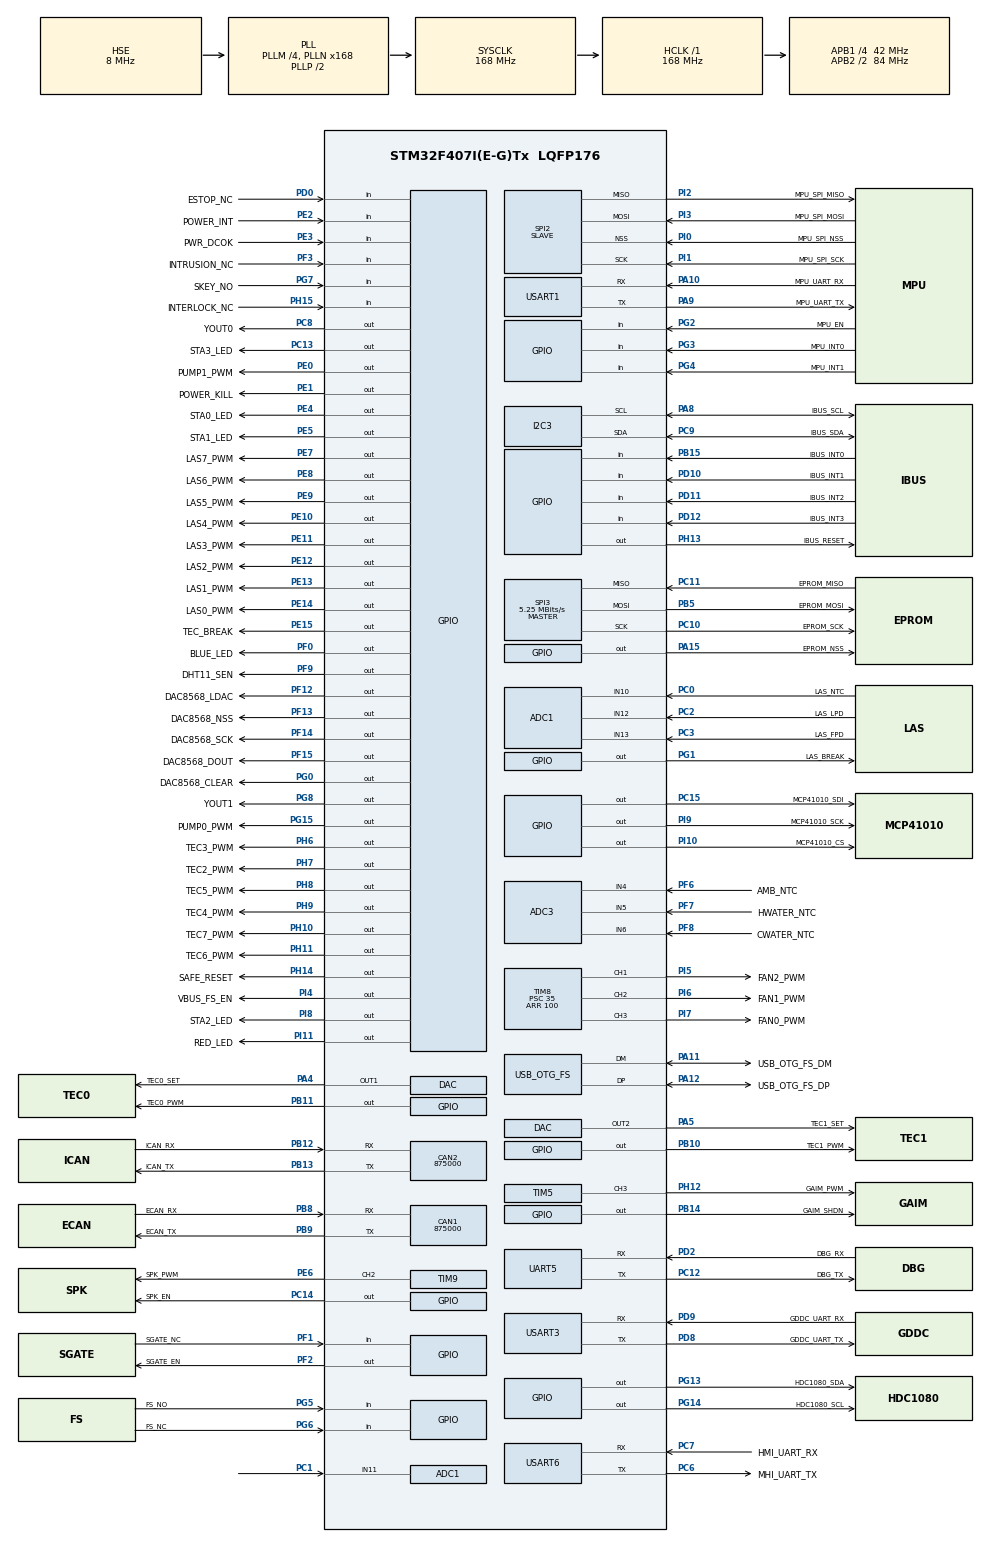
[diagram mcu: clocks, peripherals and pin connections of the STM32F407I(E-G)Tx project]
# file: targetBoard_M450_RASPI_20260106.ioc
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ADC1.Channel-0\#ChannelRegularConversion=ADC_CHANNEL_10
ADC1.Channel-1\#ChannelRegularConversion=ADC_CHANNEL_11
ADC1.Channel-2\#ChannelRegularConversion=ADC_CHANNEL_12
ADC1.Channel-3\#ChannelRegularConversion=ADC_CHANNEL_13
ADC1.Channel-4\#ChannelRegularConversion=ADC_CHANNEL_TEMPSENSOR
ADC1.Channel-5\#ChannelRegularConversion=ADC_CHANNEL_VREFINT
ADC1.Channel-6\#ChannelRegularConversion=ADC_CHANNEL_VBAT
ADC1.ContinuousConvMode=ENABLE
ADC1.DMAContinuousRequests=ENABLE
ADC1.NbrOfConversion=7
ADC1.NbrOfConversionFlag=1
ADC1.Rank-0\#ChannelRegularConversion=1
ADC1.Rank-1\#ChannelRegularConversion=2
ADC1.Rank-2\#ChannelRegularConversion=3
ADC1.Rank-3\#ChannelRegularConversion=4
ADC1.Rank-4\#ChannelRegularConversion=5
ADC1.Rank-5\#ChannelRegularConversion=6
ADC1.Rank-6\#ChannelRegularConversion=7
ADC1.SamplingTime-0\#ChannelRegularConversion=ADC_SAMPLETIME_144CYCLES
ADC1.SamplingTime-1\#ChannelRegularConversion=ADC_SAMPLETIME_144CYCLES
ADC1.SamplingTime-2\#ChannelRegularConversion=ADC_SAMPLETIME_144CYCLES
ADC1.SamplingTime-3\#ChannelRegularConversion=ADC_SAMPLETIME_144CYCLES
ADC1.SamplingTime-4\#ChannelRegularConversion=ADC_SAMPLETIME_144CYCLES
ADC1.SamplingTime-5\#ChannelRegularConversion=ADC_SAMPLETIME_144CYCLES
ADC1.SamplingTime-6\#ChannelRegularConversion=ADC_SAMPLETIME_144CYCLES
ADC1.ScanConvMode=ENABLE
ADC1.master=1
ADC3.Channel-0\#ChannelRegularConversion=ADC_CHANNEL_4
ADC3.Channel-1\#ChannelRegularConversion=ADC_CHANNEL_5
ADC3.Channel-2\#ChannelRegularConversion=ADC_CHANNEL_6
ADC3.ContinuousConvMode=ENABLE
ADC3.DMAContinuousRequests=ENABLE
ADC3.NbrOfConversion=3
ADC3.NbrOfConversionFlag=1
ADC3.Rank-0\#ChannelRegularConversion=1
ADC3.Rank-1\#ChannelRegularConversion=2
ADC3.Rank-2\#ChannelRegularConversion=3
ADC3.SamplingTime-0\#ChannelRegularConversion=ADC_SAMPLETIME_144CYCLES
ADC3.SamplingTime-1\#ChannelRegularConversion=ADC_SAMPLETIME_144CYCLES
ADC3.SamplingTime-2\#ChannelRegularConversion=ADC_SAMPLETIME_144CYCLES
ADC3.ScanConvMode=ENABLE
CAN1.BS1=CAN_BS1_1TQ
CAN1.BS2=CAN_BS2_1TQ
CAN1.CalculateBaudRate=875000
CAN1.CalculateTimeBit=1142
CAN1.CalculateTimeQuantum=380.95238095238096
CAN2.BS1=CAN_BS1_1TQ
CAN2.BS2=CAN_BS2_1TQ
CAN2.CalculateBaudRate=875000
CAN2.CalculateTimeBit=1142
CAN2.CalculateTimeQuantum=380.95238095238096
DAC.DAC_Trigger=DAC_TRIGGER_NONE
DAC.DAC_Trigger2=DAC_TRIGGER_NONE
FATFS._CODE_PAGE=437
FATFS._FS_EXFAT=1
FATFS._FS_LOCK=255
FATFS._STRF_ENCODE=0
FATFS._USE_CHMOD=0
FATFS._USE_EXPAND=0
FATFS._USE_FASTSEEK=0
FATFS._USE_FIND=0
FATFS._USE_FORWARD=0
FATFS._USE_LABEL=0
FATFS._USE_LFN=3
FATFS._USE_MKFS=0
FATFS._USE_MUTEX=1
FATFS._USE_STRFUNC=0
Mcu.Family=STM32F4
Mcu.Name=STM32F407I(E-G)Tx
Mcu.Package=LQFP176
NVIC.OTG_FS_IRQn=true\:0\:0\:false\:false\:true\:false\:true\:true
NVIC.PriorityGroup=NVIC_PRIORITYGROUP_4
NVIC.TIM6_DAC_IRQn=true\:15\:0\:false\:false\:true\:false\:true\:true
NVIC.TIM8_TRG_COM_TIM14_IRQn=true\:0\:0\:false\:false\:true\:true\:true\:true
NVIC.TIM8_UP_TIM13_IRQn=true\:15\:0\:false\:false\:true\:false\:true\:true
NVIC.TimeBase=TIM6_DAC_IRQn
NVIC.TimeBaseIP=TIM6
NVIC.USART3_IRQn=true\:0\:0\:false\:false\:true\:true\:true\:true
PA10.GPIO_Label=MPU_UART_RX
PA10.GPIO_PuPd=GPIO_PULLDOWN
PA10.GPIO_Speed=GPIO_SPEED_FREQ_HIGH
PA10.Mode=Asynchronous
PA10.Signal=USART1_RX
PA11.GPIO_Label=USB_OTG_FS_DM
PA11.Mode=Host_Only
PA11.Signal=USB_OTG_FS_DM
PA12.GPIO_Label=USB_OTG_FS_DP
PA12.Mode=Host_Only
PA12.Signal=USB_OTG_FS_DP
PA13.GPIO_Label=SWDIO
PA13.Mode=Trace_Asynchronous_SW
PA13.Signal=SYS_JTMS-SWDIO
PA14.GPIO_Label=SWCLK
PA14.Mode=Trace_Asynchronous_SW
PA14.Signal=SYS_JTCK-SWCLK
PA15.GPIO_Label=EPROM_NSS
PA15.GPIO_PuPd=GPIO_PULLUP
PA15.GPIO_Speed=GPIO_SPEED_FREQ_VERY_HIGH
PA15.Signal=GPIO_Output
PA4.GPIO_Label=TEC0_SET
PA4.Signal=COMP_DAC1_group
PA5.GPIO_Label=TEC1_SET
PA5.Signal=COMP_DAC2_group
PA8.GPIO_Label=IBUS_SCL
PA8.GPIO_Pu=GPIO_PULLUP
PA8.GPIO_Speed=GPIO_SPEED_FREQ_HIGH
PA8.Mode=I2C
PA8.Signal=I2C3_SCL
PA9.GPIO_Label=MPU_UART_TX
PA9.GPIO_PuPd=GPIO_PULLDOWN
PA9.GPIO_Speed=GPIO_SPEED_FREQ_HIGH
PA9.Mode=Asynchronous
PA9.Signal=USART1_TX
PB10.GPIO_Label=TEC1_PWM
PB10.GPIO_PuPd=GPIO_PULLDOWN
PB10.Signal=GPIO_Output
PB11.GPIO_Label=TEC0_PWM
PB11.GPIO_PuPd=GPIO_PULLDOWN
PB11.Signal=GPIO_Output
PB12.GPIO_Label=ICAN_RX
PB12.Mode=CAN_Activate
PB12.Signal=CAN2_RX
PB13.GPIO_Label=ICAN_TX
PB13.Mode=CAN_Activate
PB13.Signal=CAN2_TX
PB14.GPIO_Label=GAIM_SHDN
PB14.Signal=GPIO_Output
PB15.GPIO_Label=IBUS_INT0
PB15.GPIO_PuPd=GPIO_PULLUP
PB15.Signal=GPIO_Input
PB3.GPIO_Label=SWO
PB3.Mode=Trace_Asynchronous_SW
PB3.Signal=SYS_JTDO-SWO
PB5.GPIO_Label=EPROM_MOSI
PB5.GPIO_PuPd=GPIO_PULLDOWN
PB5.Mode=Full_Duplex_Master
PB5.Signal=SPI3_MOSI
PB8.GPIO_Label=ECAN_RX
PB8.Mode=CAN_Activate
PB8.Signal=CAN1_RX
PB9.GPIO_Label=ECAN_TX
PB9.Mode=CAN_Activate
PB9.Signal=CAN1_TX
PC0.GPIO_Label=LAS_NTC
PC0.Signal=ADCx_IN10
PC1.Signal=ADCx_IN11
PC10.GPIO_Label=EPROM_SCK
PC10.GPIO_PuPd=GPIO_PULLDOWN
PC10.Mode=Full_Duplex_Master
PC10.Signal=SPI3_SCK
PC11.GPIO_Label=EPROM_MISO
PC11.GPIO_PuPd=GPIO_PULLDOWN
PC11.Mode=Full_Duplex_Master
PC11.Signal=SPI3_MISO
PC12.GPIO_Label=DBG_TX
PC12.GPIO_PuPd=GPIO_PULLDOWN
PC12.GPIO_Speed=GPIO_SPEED_FREQ_HIGH
PC12.Mode=Asynchronous
PC12.Signal=UART5_TX
PC13-ANTI_TAMP.GPIO_Label=STA3_LED
PC13-ANTI_TAMP.GPIO_ModeDefaultOutputPP=GPIO_MODE_OUTPUT_OD
PC13-ANTI_TAMP.GPIO_PuPd=GPIO_NOPULL
PC13-ANTI_TAMP.Signal=GPIO_Output
PC14-OSC32_IN.GPIO_Label=SPK_EN
PC14-OSC32_IN.GPIO_PuPd=GPIO_PULLUP
PC14-OSC32_IN.Signal=GPIO_Output
PC15-OSC32_OUT.GPIO_Label=MCP41010_SDI
PC15-OSC32_OUT.GPIO_PuPd=GPIO_PULLDOWN
PC15-OSC32_OUT.Signal=GPIO_Output
PC2.GPIO_Label=LAS_LPD
PC2.Signal=ADCx_IN12
PC3.GPIO_Label=LAS_FPD
PC3.Signal=ADCx_IN13
PC6.GPIO_Label=MHI_UART_TX
PC6.GPIO_PuPd=GPIO_PULLDOWN
PC6.GPIO_Speed=GPIO_SPEED_FREQ_HIGH
PC6.Mode=Asynchronous
PC6.Signal=USART6_TX
PC7.GPIO_Label=HMI_UART_RX
PC7.GPIO_PuPd=GPIO_PULLDOWN
PC7.GPIO_Speed=GPIO_SPEED_FREQ_HIGH
PC7.Mode=Asynchronous
PC7.Signal=USART6_RX
PC8.GPIO_Label=YOUT0
PC8.GPIO_PuPd=GPIO_PULLDOWN
PC8.Signal=GPIO_Output
PC9.GPIO_Label=IBUS_SDA
PC9.GPIO_Pu=GPIO_PULLUP
PC9.GPIO_Speed=GPIO_SPEED_FREQ_HIGH
PC9.Mode=I2C
PC9.Signal=I2C3_SDA
PD0.GPIO_Label=ESTOP_NC
PD0.GPIO_PuPd=GPIO_PULLUP
PD0.Signal=GPIO_Input
PD10.GPIO_Label=IBUS_INT1
PD10.GPIO_PuPd=GPIO_PULLUP
PD10.Signal=GPIO_Input
PD11.GPIO_Label=IBUS_INT2
PD11.GPIO_PuPd=GPIO_PULLUP
PD11.Signal=GPIO_Input
PD12.GPIO_Label=IBUS_INT3
PD12.GPIO_PuPd=GPIO_PULLUP
PD12.Signal=GPIO_Input
PD2.GPIO_Label=DBG_RX
PD2.GPIO_PuPd=GPIO_PULLDOWN
PD2.GPIO_Speed=GPIO_SPEED_FREQ_HIGH
PD2.Mode=Asynchronous
PD2.Signal=UART5_RX
PD8.GPIO_Label=GDDC_UART_TX
PD8.GPIO_PuPd=GPIO_PULLDOWN
PD8.GPIO_Speed=GPIO_SPEED_FREQ_HIGH
PD8.Mode=Asynchronous
PD8.Signal=USART3_TX
PD9.GPIO_Label=GDDC_UART_RX
PD9.GPIO_PuPd=GPIO_PULLDOWN
PD9.GPIO_Speed=GPIO_SPEED_FREQ_HIGH
PD9.Mode=Asynchronous
PD9.Signal=USART3_RX
PE0.GPIO_Label=PUMP1_PWM
PE0.GPIO_PuPd=GPIO_PULLUP
PE0.Signal=GPIO_Output
PE1.GPIO_Label=POWER_KILL
PE1.GPIO_ModeDefaultOutputPP=GPIO_MODE_OUTPUT_OD
PE1.GPIO_PuPd=GPIO_NOPULL
PE1.PinState=GPIO_PIN_SET
PE1.Signal=GPIO_Output
PE10.GPIO_Label=LAS4_PWM
PE10.GPIO_PuPd=GPIO_PULLDOWN
PE10.Signal=GPIO_Output
PE11.GPIO_Label=LAS3_PWM
PE11.GPIO_PuPd=GPIO_PULLDOWN
PE11.Signal=GPIO_Output
PE12.GPIO_Label=LAS2_PWM
PE12.GPIO_PuPd=GPIO_PULLDOWN
PE12.Signal=GPIO_Output
PE13.GPIO_Label=LAS1_PWM
PE13.GPIO_PuPd=GPIO_PULLDOWN
PE13.Signal=GPIO_Output
PE14.GPIO_Label=LAS0_PWM
PE14.GPIO_PuPd=GPIO_PULLDOWN
PE14.Signal=GPIO_Output
PE15.GPIO_Label=TEC_BREAK
PE15.GPIO_PuPd=GPIO_PULLDOWN
PE15.Signal=GPIO_Output
PE2.GPIO_Label=POWER_INT
PE2.GPIO_PuPd=GPIO_PULLUP
PE2.Signal=GPIO_Input
PE3.GPIO_Label=PWR_DCOK
PE3.GPIO_PuPd=GPIO_PULLUP
PE3.Signal=GPIO_Input
PE4.GPIO_Label=STA0_LED
PE4.GPIO_ModeDefaultOutputPP=GPIO_MODE_OUTPUT_OD
PE4.GPIO_PuPd=GPIO_NOPULL
PE4.Signal=GPIO_Output
PE5.GPIO_Label=STA1_LED
PE5.GPIO_ModeDefaultOutputPP=GPIO_MODE_OUTPUT_OD
PE5.GPIO_PuPd=GPIO_NOPULL
PE5.Signal=GPIO_Output
PE6.GPIO_Label=SPK_PWM
PE6.GPIO_PuPd=GPIO_PULLDOWN
PE6.Signal=S_TIM9_CH2
PE7.GPIO_Label=LAS7_PWM
PE7.GPIO_PuPd=GPIO_PULLDOWN
PE7.Signal=GPIO_Output
PE8.GPIO_Label=LAS6_PWM
PE8.GPIO_PuPd=GPIO_PULLDOWN
PE8.Signal=GPIO_Output
PE9.GPIO_Label=LAS5_PWM
PE9.GPIO_PuPd=GPIO_PULLDOWN
PE9.Signal=GPIO_Output
PF0.GPIO_Label=BLUE_LED
PF0.GPIO_PuPd=GPIO_PULLDOWN
PF0.Signal=GPIO_Output
PF1.GPIO_Label=SGATE_NC
PF1.GPIO_PuPd=GPIO_PULLDOWN
PF1.Signal=GPIO_Input
PF12.GPIO_Label=DAC8568_LDAC
PF12.GPIO_PuPd=GPIO_PULLUP
PF12.Signal=GPIO_Output
PF13.GPIO_Label=DAC8568_NSS
PF13.GPIO_PuPd=GPIO_PULLUP
PF13.Signal=GPIO_Output
PF14.GPIO_Label=DAC8568_SCK
PF14.GPIO_PuPd=GPIO_PULLDOWN
PF14.Signal=GPIO_Output
PF15.GPIO_Label=DAC8568_DOUT
PF15.GPIO_PuPd=GPIO_PULLDOWN
PF15.Signal=GPIO_Output
PF2.GPIO_Label=SGATE_EN
PF2.GPIO_PuPd=GPIO_PULLDOWN
PF2.Signal=GPIO_Output
PF3.GPIO_Label=INTRUSION_NC
PF3.GPIO_PuPd=GPIO_PULLUP
PF3.Signal=GPIO_Input
PF6.GPIO_Label=AMB_NTC
PF6.Mode=IN4
PF6.Signal=ADC3_IN4
PF7.GPIO_Label=HWATER_NTC
PF7.Mode=IN5
PF7.Signal=ADC3_IN5
PF8.GPIO_Label=CWATER_NTC
PF8.Mode=IN6
PF8.Signal=ADC3_IN6
PF9.GPIO_Label=DHT11_SEN
PF9.GPIO_PuPd=GPIO_PULLUP
PF9.Signal=GPIO_Output
PG0.GPIO_Label=DAC8568_CLEAR
PG0.GPIO_PuPd=GPIO_PULLUP
PG0.Signal=GPIO_Output
PG1.GPIO_Label=LAS_BREAK
PG1.GPIO_PuPd=GPIO_PULLDOWN
PG1.Signal=GPIO_Output
PG13.GPIO_Label=HDC1080_SDA
PG13.GPIO_ModeDefaultOutputPP=GPIO_MODE_OUTPUT_OD
PG13.GPIO_PuPd=GPIO_NOPULL
PG13.GPIO_Speed=GPIO_SPEED_FREQ_HIGH
PG13.PinState=GPIO_PIN_SET
PG13.Signal=GPIO_Output
PG14.GPIO_Label=HDC1080_SCL
PG14.GPIO_ModeDefaultOutputPP=GPIO_MODE_OUTPUT_OD
PG14.GPIO_PuPd=GPIO_NOPULL
PG14.GPIO_Speed=GPIO_SPEED_FREQ_HIGH
PG14.PinState=GPIO_PIN_SET
PG14.Signal=GPIO_Output
PG15.GPIO_Label=PUMP0_PWM
PG15.GPIO_PuPd=GPIO_PULLUP
PG15.Signal=GPIO_Output
PG2.GPIO_Label=MPU_EN
PG2.GPIO_PuPd=GPIO_PULLUP
PG2.Signal=GPIO_Input
PG3.GPIO_Label=MPU_INT0
PG3.GPIO_PuPd=GPIO_PULLUP
PG3.Signal=GPIO_Input
PG4.GPIO_Label=MPU_INT1
PG4.GPIO_PuPd=GPIO_PULLUP
PG4.Signal=GPIO_Input
PG5.GPIO_Label=FS_NO
PG5.GPIO_PuPd=GPIO_PULLUP
PG5.Signal=GPIO_Input
PG6.GPIO_Label=FS_NC
PG6.GPIO_PuPd=GPIO_PULLUP
PG6.Signal=GPIO_Input
PG7.GPIO_Label=SKEY_NO
PG7.GPIO_PuPd=GPIO_PULLUP
PG7.Signal=GPIO_Input
PG8.GPIO_Label=YOUT1
PG8.GPIO_PuPd=GPIO_PULLDOWN
PG8.Signal=GPIO_Output
PH0-OSC_IN.Mode=HSE-External-Oscillator
PH0-OSC_IN.Signal=RCC_OSC_IN
PH1-OSC_OUT.Mode=HSE-External-Oscillator
PH1-OSC_OUT.Signal=RCC_OSC_OUT
PH10.GPIO_Label=TEC7_PWM
PH10.GPIO_PuPd=GPIO_PULLDOWN
PH10.Signal=GPIO_Output
PH11.GPIO_Label=TEC6_PWM
PH11.GPIO_PuPd=GPIO_PULLDOWN
PH11.Signal=GPIO_Output
PH12.GPIO_Label=GAIM_PWM
PH12.GPIO_PuPd=GPIO_PULLDOWN
PH12.Signal=S_TIM5_CH3
PH13.GPIO_Label=IBUS_RESET
PH13.GPIO_PuPd=GPIO_PULLUP
PH13.Signal=GPIO_Output
PH14.GPIO_Label=SAFE_RESET
PH14.GPIO_PuPd=GPIO_PULLUP
PH14.Signal=GPIO_Output
PH15.GPIO_Label=INTERLOCK_NC
PH15.GPIO_PuPd=GPIO_PULLUP
PH15.Signal=GPIO_Input
PH6.GPIO_Label=TEC3_PWM
PH6.GPIO_PuPd=GPIO_PULLDOWN
PH6.Signal=GPIO_Output
PH7.GPIO_Label=TEC2_PWM
PH7.GPIO_PuPd=GPIO_PULLDOWN
PH7.Signal=GPIO_Output
PH8.GPIO_Label=TEC5_PWM
PH8.GPIO_PuPd=GPIO_PULLDOWN
PH8.Signal=GPIO_Output
PH9.GPIO_Label=TEC4_PWM
PH9.GPIO_PuPd=GPIO_PULLDOWN
PH9.Signal=GPIO_Output
PI0.GPIO_Label=MPU_SPI_NSS
PI0.GPIO_PuPd=GPIO_PULLUP
PI0.GPIO_Speed=GPIO_SPEED_FREQ_VERY_HIGH
PI0.Mode=NSS_Signal_Hard_Input
PI0.Signal=SPI2_NSS
PI1.GPIO_Label=MPU_SPI_SCK
PI1.GPIO_PuPd=GPIO_PULLDOWN
PI1.Mode=Full_Duplex_Slave
PI1.Signal=SPI2_SCK
PI10.GPIO_Label=MCP41010_CS
PI10.GPIO_PuPd=GPIO_PULLUP
PI10.Signal=GPIO_Output
PI11.GPIO_Label=RED_LED
PI11.GPIO_PuPd=GPIO_PULLDOWN
PI11.Signal=GPIO_Output
PI2.GPIO_Label=MPU_SPI_MISO
PI2.GPIO_PuPd=GPIO_PULLDOWN
PI2.Mode=Full_Duplex_Slave
PI2.Signal=SPI2_MISO
PI3.GPIO_Label=MPU_SPI_MOSI
PI3.GPIO_PuPd=GPIO_PULLDOWN
PI3.Mode=Full_Duplex_Slave
PI3.Signal=SPI2_MOSI
PI4.GPIO_Label=VBUS_FS_EN
PI4.GPIO_PuPd=GPIO_PULLDOWN
PI4.Signal=GPIO_Output
PI5.GPIO_Label=FAN2_PWM
PI5.GPIO_PuPd=GPIO_PULLUP
PI5.Signal=S_TIM8_CH1
PI6.GPIO_Label=FAN1_PWM
PI6.GPIO_PuPd=GPIO_PULLUP
PI6.Signal=S_TIM8_CH2
PI7.GPIO_Label=FAN0_PWM
PI7.GPIO_PuPd=GPIO_PULLUP
PI7.Signal=S_TIM8_CH3
PI8-\ ANTI\ TAMP2.GPIO_Label=STA2_LED
PI8-\ ANTI\ TAMP2.GPIO_ModeDefaultOutputPP=GPIO_MODE_OUTPUT_OD
PI8-\ ANTI\ TAMP2.GPIO_PuPd=GPIO_NOPULL
PI8-\ ANTI\ TAMP2.Signal=GPIO_Output
PI9.GPIO_Label=MCP41010_SCK
PI9.GPIO_PuPd=GPIO_PULLDOWN
PI9.Signal=GPIO_Output
ProjectManager.HeapSize=0x2000
ProjectManager.StackSize=0x2000
ProjectManager.TargetToolchain=MDK-ARM V5.32
RCC.48MHZClocksFreq_Value=48000000
RCC.AHBFreq_Value=168000000
RCC.APB1CLKDivider=RCC_HCLK_DIV4
RCC.APB1Freq_Value=42000000
RCC.APB1TimFreq_Value=84000000
RCC.APB2CLKDivider=RCC_HCLK_DIV2
RCC.APB2Freq_Value=84000000
RCC.APB2TimFreq_Value=168000000
RCC.CortexFreq_Value=168000000
RCC.HCLKFreq_Value=168000000
RCC.HSE_VALUE=8000000
RCC.HSI_VALUE=16000000
RCC.LSE_VALUE=32768
RCC.PLLM=4
RCC.PLLN=168
RCC.PLLQ=7
RCC.SYSCLKFreq_VALUE=168000000
RCC.SYSCLKSource=RCC_SYSCLKSOURCE_PLLCLK
RCC.VCOOutputFreq_Value=336000000
SH.ADCx_IN10.0=ADC1_IN10,IN10
SH.ADCx_IN11.0=ADC1_IN11,IN11
SH.ADCx_IN12.0=ADC1_IN12,IN12
SH.ADCx_IN13.0=ADC1_IN13,IN13
SH.COMP_DAC1_group.0=DAC_OUT1,DAC_OUT1
SH.COMP_DAC2_group.0=DAC_OUT2,DAC_OUT2
SH.S_TIM5_CH3.0=TIM5_CH3,PWM Generation3 CH3
SH.S_TIM8_CH1.0=TIM8_CH1,PWM Generation1 CH1
SH.S_TIM8_CH2.0=TIM8_CH2,PWM Generation2 CH2
SH.S_TIM8_CH3.0=TIM8_CH3,PWM Generation3 CH3
SH.S_TIM9_CH2.0=TIM9_CH2,PWM Generation2 CH2
SPI2.Direction=SPI_DIRECTION_2LINES
SPI2.Mode=SPI_MODE_SLAVE
SPI2.VirtualNSS=VM_NSSHARD
SPI2.VirtualType=VM_SLAVE
SPI3.BaudRatePrescaler=SPI_BAUDRATEPRESCALER_8
SPI3.CalculateBaudRate=5.25 MBits/s
SPI3.Direction=SPI_DIRECTION_2LINES
SPI3.FirstBit=SPI_FIRSTBIT_MSB
SPI3.Mode=SPI_MODE_MASTER
SPI3.VirtualType=VM_MASTER
TIM14.AutoReloadPreload=TIM_AUTORELOAD_PRELOAD_DISABLE
TIM14.Period=1000
TIM14.Prescaler=84
TIM5.AutoReloadPreload=TIM_AUTORELOAD_PRELOAD_ENABLE
TIM5.Channel-PWM\ Generation3\ CH3=TIM_CHANNEL_3
TIM5.Period=5000
TIM5.Prescaler=96
TIM7.AutoReloadPreload=TIM_AUTORELOAD_PRELOAD_ENABLE
TIM7.Period=1000
TIM7.Prescaler=84
TIM8.AutoReloadPreload=TIM_AUTORELOAD_PRELOAD_ENABLE
TIM8.Channel-PWM\ Generation1\ CH1=TIM_CHANNEL_1
TIM8.Channel-PWM\ Generation2\ CH2=TIM_CHANNEL_2
TIM8.Channel-PWM\ Generation3\ CH3=TIM_CHANNEL_3
TIM8.Period=100
TIM8.Prescaler=35
TIM9.AutoReloadPreload=TIM_AUTORELOAD_PRELOAD_ENABLE
TIM9.Channel-PWM\ Generation2\ CH2=TIM_CHANNEL_2
TIM9.Period=1000
TIM9.Prescaler=1000
UART5.VirtualMode=Asynchronous
USART1.VirtualMode=VM_ASYNC
USART3.VirtualMode=VM_ASYNC
USART6.VirtualMode=VM_ASYNC
USB_HOST.BSP.number=1
USB_HOST.USBH_DEBUG_LEVEL-MSC_FS=3
USB_HOST.USBH_HandleTypeDef-MSC_FS=hUsbHostFS
USB_HOST.VirtualModeFS=Msc
USB_HOST0.BSP.STBoard=false
USB_HOST0.BSP.api=Unknown
USB_HOST0.BSP.condition=ALL_SW_VBUS_DRIVE_FS \= false
USB_HOST0.BSP.instance=PI4
USB_HOST0.BSP.ip=GPIO
USB_HOST0.BSP.mode=Output
USB_HOST0.BSP.name=Drive_VBUS_FS
USB_HOST0.BSP.solution=PI4
USB_OTG_FS.VirtualMode=Host_Only
USB_OTG_FS.phy_itface=HCD_PHY_EMBEDDED
VP_ADC1_TempSens_Input.Mode=IN-TempSens
VP_ADC1_Vbat_Input.Mode=IN-Vbat
VP_ADC1_Vref_Input.Mode=IN-Vrefint
VP_CRC_VS_CRC.Mode=CRC_Activate
VP_FATFS_VS_USB.Mode=USB
VP_RNG_VS_RNG.Mode=RNG_Activate
VP_SYS_VS_tim6.Mode=TIM6
VP_TIM12_VS_ClockSourceINT.Mode=Internal
VP_TIM14_VS_ClockSourceINT.Mode=Enable_Timer
VP_TIM5_VS_ClockSourceINT.Mode=Internal
VP_TIM7_VS_ClockSourceINT.Mode=Enable_Timer
VP_TIM8_VS_ClockSourceINT.Mode=Internal
VP_TIM9_VS_ClockSourceINT.Mode=Internal
VP_USB_HOST_VS_USB_HOST_MSC_FS.Mode=MSC_FS
board=custom

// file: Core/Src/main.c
/*----------------------------------------------------------------------------
 * 文件编码约定: 本文件为 UTF-8 编码(带BOM)。
 * 本工程源码统一使用 UTF-8(带BOM) 保存: 新建或修改任何源文件时,
 * 请以 UTF-8 编码保存, 并在文件头保留本注释。
 *----------------------------------------------------------------------------*/
/* USER CODE BEGIN Header */
/**
  ******************************************************************************
  * @file           : main.c
  * @brief          : Main program body
  ******************************************************************************
  * @attention
  *
  * Copyright (c) 2026 STMicroelectronics.
  * All rights reserved.
  *
  * This software is licensed under terms that can be found in the LICENSE file
  * in the root directory of this software component.
  * If no LICENSE file comes with this software, it is provided AS-IS.
  *
  ******************************************************************************
  */
/* USER CODE END Header */
#include "main.h"
#include "adc.h"
#include "can.h"
#include "crc.h"
#include "dac.h"
#include "fatfs.h"
#include "i2c.h"
#include "rng.h"
#include "spi.h"
#include "tim.h"
#include "usart.h"
#include "usb_host.h"
#include "gpio.h"

/* USER CODE BEGIN PTD */
extern void bootLoadProcess(void);//bootload 执行程序
/* USER CODE END PTD */

void SystemClock_Config(void);
void MX_USB_HOST_Process(void);

int main(void)
{

  /* MCU Configuration--------------------------------------------------------*/

  /* Reset of all peripherals, Initializes the Flash interface and the Systick. */
  HAL_Init();

  /* Configure the system clock */
  SystemClock_Config();

  /* Initialize all configured peripherals */
  MX_GPIO_Init();
  MX_ADC1_Init();
  MX_CAN1_Init();
  MX_CAN2_Init();
  MX_CRC_Init();
  MX_DAC_Init();
  MX_I2C3_Init();
  MX_RNG_Init();
  MX_SPI2_Init();
  MX_SPI3_Init();
  MX_TIM12_Init();
  MX_UART5_Init();
  MX_USART1_UART_Init();
  MX_USART3_UART_Init();
  MX_USART6_UART_Init();
  MX_TIM5_Init();
  MX_TIM8_Init();
  MX_TIM9_Init();
  MX_FATFS_Init();
  MX_USB_HOST_Init();
  MX_TIM7_Init();
  MX_TIM14_Init();
  MX_ADC3_Init();

  /* Infinite loop */
  while (1)
  {
    MX_USB_HOST_Process();

    /* USER CODE BEGIN 3 */
		bootLoadProcess();
  }
  /* USER CODE END 3 */
}

void SystemClock_Config(void)
{
  RCC_OscInitTypeDef RCC_OscInitStruct = {0};
  RCC_ClkInitTypeDef RCC_ClkInitStruct = {0};

  /** Configure the main internal regulator output voltage
  */
  __HAL_RCC_PWR_CLK_ENABLE();
  __HAL_PWR_VOLTAGESCALING_CONFIG(PWR_REGULATOR_VOLTAGE_SCALE1);

  /** Initializes the RCC Oscillators according to the specified parameters
  * in the RCC_OscInitTypeDef structure.
  */
  RCC_OscInitStruct.OscillatorType = RCC_OSCILLATORTYPE_HSE;
  RCC_OscInitStruct.HSEState = RCC_HSE_ON;
  RCC_OscInitStruct.PLL.PLLState = RCC_PLL_ON;
  RCC_OscInitStruct.PLL.PLLSource = RCC_PLLSOURCE_HSE;
  RCC_OscInitStruct.PLL.PLLM = 4;
  RCC_OscInitStruct.PLL.PLLN = 168;
  RCC_OscInitStruct.PLL.PLLP = RCC_PLLP_DIV2;
  RCC_OscInitStruct.PLL.PLLQ = 7;
  if (HAL_RCC_OscConfig(&RCC_OscInitStruct) != HAL_OK)
  {
    Error_Handler();
  }

  /** Initializes the CPU, AHB and APB buses clocks
  */
  RCC_ClkInitStruct.ClockType = RCC_CLOCKTYPE_HCLK|RCC_CLOCKTYPE_SYSCLK
                              |RCC_CLOCKTYPE_PCLK1|RCC_CLOCKTYPE_PCLK2;
  RCC_ClkInitStruct.SYSCLKSource = RCC_SYSCLKSOURCE_PLLCLK;
  RCC_ClkInitStruct.AHBCLKDivider = RCC_SYSCLK_DIV1;
  RCC_ClkInitStruct.APB1CLKDivider = RCC_HCLK_DIV4;
  RCC_ClkInitStruct.APB2CLKDivider = RCC_HCLK_DIV2;

  if (HAL_RCC_ClockConfig(&RCC_ClkInitStruct, FLASH_LATENCY_5) != HAL_OK)
  {
    Error_Handler();
  }
}

void HAL_TIM_PeriodElapsedCallback(TIM_HandleTypeDef *htim)
{
  if (htim->Instance == TIM13)
  {
    HAL_IncTick();
  }
}

void Error_Handler(void)
{
  __disable_irq();
  while (1)
  {
  }
}
